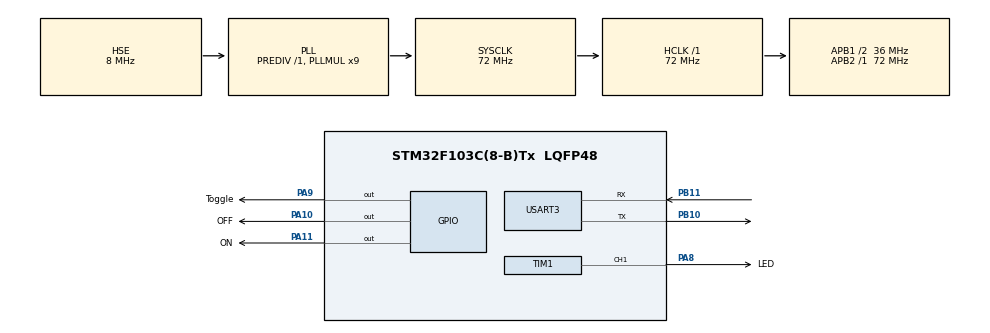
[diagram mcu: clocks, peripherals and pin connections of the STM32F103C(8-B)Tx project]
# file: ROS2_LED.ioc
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Dma.Request0=USART3_TX
Dma.Request1=USART3_RX
Dma.USART3_RX.1.Direction=DMA_PERIPH_TO_MEMORY
Dma.USART3_RX.1.Instance=DMA1_Channel3
Dma.USART3_RX.1.MemDataAlignment=DMA_MDATAALIGN_BYTE
Dma.USART3_RX.1.MemInc=DMA_MINC_ENABLE
Dma.USART3_RX.1.Mode=DMA_CIRCULAR
Dma.USART3_RX.1.PeriphDataAlignment=DMA_PDATAALIGN_BYTE
Dma.USART3_RX.1.PeriphInc=DMA_PINC_DISABLE
Dma.USART3_RX.1.Priority=DMA_PRIORITY_LOW
Dma.USART3_TX.0.Direction=DMA_MEMORY_TO_PERIPH
Dma.USART3_TX.0.Instance=DMA1_Channel2
Dma.USART3_TX.0.MemDataAlignment=DMA_MDATAALIGN_BYTE
Dma.USART3_TX.0.MemInc=DMA_MINC_ENABLE
Dma.USART3_TX.0.Mode=DMA_NORMAL
Dma.USART3_TX.0.PeriphDataAlignment=DMA_PDATAALIGN_BYTE
Dma.USART3_TX.0.PeriphInc=DMA_PINC_DISABLE
Dma.USART3_TX.0.Priority=DMA_PRIORITY_LOW
Mcu.Family=STM32F1
Mcu.Name=STM32F103C(8-B)Tx
Mcu.Package=LQFP48
NVIC.DMA1_Channel2_IRQn=true\:0\:0\:false\:false\:true\:false\:true\:true
NVIC.DMA1_Channel3_IRQn=true\:0\:0\:false\:false\:true\:false\:true\:true
NVIC.PriorityGroup=NVIC_PRIORITYGROUP_4
NVIC.TIM2_IRQn=true\:0\:0\:false\:false\:true\:true\:true\:true
NVIC.USART3_IRQn=true\:0\:0\:false\:false\:true\:true\:true\:true
PA10.GPIO_Label=OFF
PA10.Signal=GPIO_Output
PA11.GPIO_Label=ON
PA11.Signal=GPIO_Output
PA13.Mode=Serial_Wire
PA13.Signal=SYS_JTMS-SWDIO
PA14.Mode=Serial_Wire
PA14.Signal=SYS_JTCK-SWCLK
PA8.GPIO_Label=LED
PA8.Signal=S_TIM1_CH1
PA9.GPIO_Label=Toggle
PA9.Signal=GPIO_Output
PB10.Mode=Asynchronous
PB10.Signal=USART3_TX
PB11.Mode=Asynchronous
PB11.Signal=USART3_RX
PD0-OSC_IN.Mode=HSE-External-Oscillator
PD0-OSC_IN.Signal=RCC_OSC_IN
PD1-OSC_OUT.Mode=HSE-External-Oscillator
PD1-OSC_OUT.Signal=RCC_OSC_OUT
ProjectManager.HeapSize=0x200
ProjectManager.StackSize=0x400
ProjectManager.TargetToolchain=MDK-ARM V5.32
RCC.AHBFreq_Value=72000000
RCC.APB1CLKDivider=RCC_HCLK_DIV2
RCC.APB1Freq_Value=36000000
RCC.APB1TimFreq_Value=72000000
RCC.APB2Freq_Value=72000000
RCC.APB2TimFreq_Value=72000000
RCC.HCLKFreq_Value=72000000
RCC.PLLMUL=RCC_PLL_MUL9
RCC.PLLSourceVirtual=RCC_PLLSOURCE_HSE
RCC.SYSCLKFreq_VALUE=72000000
RCC.SYSCLKSource=RCC_SYSCLKSOURCE_PLLCLK
RCC.USBFreq_Value=72000000
SH.S_TIM1_CH1.0=TIM1_CH1,PWM Generation1 CH1
TIM1.Channel-PWM\ Generation1\ CH1=TIM_CHANNEL_1
TIM1.Period=500-1
TIM1.Prescaler=72-1
TIM2.Period=2000-1
TIM2.Prescaler=7200-1
USART3.VirtualMode=VM_ASYNC
VP_TIM2_VS_ClockSourceINT.Mode=Internal
board=custom

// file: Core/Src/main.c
/* USER CODE BEGIN Header */
/**
  ******************************************************************************
  * @file           : main.c
  * @brief          : Main program body
  ******************************************************************************
  * @attention
  *
  * Copyright (c) 2026 STMicroelectronics.
  * All rights reserved.
  *
  * This software is licensed under terms that can be found in the LICENSE file
  * in the root directory of this software component.
  * If no LICENSE file comes with this software, it is provided AS-IS.
  *
  ******************************************************************************
  */
/* USER CODE END Header */
#include "main.h"
#include "dma.h"
#include "tim.h"
#include "usart.h"
#include "gpio.h"

/* USER CODE BEGIN Includes */
#include "SM.h"
/* USER CODE END Includes */

void SystemClock_Config(void);

int main(void)
{

  /* MCU Configuration--------------------------------------------------------*/

  /* Reset of all peripherals, Initializes the Flash interface and the Systick. */
  HAL_Init();

  /* Configure the system clock */
  SystemClock_Config();

  /* Initialize all configured peripherals */
  MX_GPIO_Init();
  MX_DMA_Init();
  MX_TIM1_Init();
  MX_USART3_UART_Init();
  MX_TIM2_Init();
  /* USER CODE BEGIN 2 */
  HAL_TIM_Base_Start(&htim1);
	HAL_TIM_Base_Start_IT(&htim2);
  HAL_UARTEx_ReceiveToIdle_DMA(&huart3, (uint8_t*)rx_buffer, sizeof(rx_buffer));
  /* USER CODE END 2 */

  /* Infinite loop */
  while (1)
  {

  }
}

void SystemClock_Config(void)
{
  RCC_OscInitTypeDef RCC_OscInitStruct = {0};
  RCC_ClkInitTypeDef RCC_ClkInitStruct = {0};

  /** Initializes the RCC Oscillators according to the specified parameters
  * in the RCC_OscInitTypeDef structure.
  */
  RCC_OscInitStruct.OscillatorType = RCC_OSCILLATORTYPE_HSE;
  RCC_OscInitStruct.HSEState = RCC_HSE_ON;
  RCC_OscInitStruct.HSEPredivValue = RCC_HSE_PREDIV_DIV1;
  RCC_OscInitStruct.HSIState = RCC_HSI_ON;
  RCC_OscInitStruct.PLL.PLLState = RCC_PLL_ON;
  RCC_OscInitStruct.PLL.PLLSource = RCC_PLLSOURCE_HSE;
  RCC_OscInitStruct.PLL.PLLMUL = RCC_PLL_MUL9;
  if (HAL_RCC_OscConfig(&RCC_OscInitStruct) != HAL_OK)
  {
    Error_Handler();
  }

  /** Initializes the CPU, AHB and APB buses clocks
  */
  RCC_ClkInitStruct.ClockType = RCC_CLOCKTYPE_HCLK|RCC_CLOCKTYPE_SYSCLK
                              |RCC_CLOCKTYPE_PCLK1|RCC_CLOCKTYPE_PCLK2;
  RCC_ClkInitStruct.SYSCLKSource = RCC_SYSCLKSOURCE_PLLCLK;
  RCC_ClkInitStruct.AHBCLKDivider = RCC_SYSCLK_DIV1;
  RCC_ClkInitStruct.APB1CLKDivider = RCC_HCLK_DIV2;
  RCC_ClkInitStruct.APB2CLKDivider = RCC_HCLK_DIV1;

  if (HAL_RCC_ClockConfig(&RCC_ClkInitStruct, FLASH_LATENCY_2) != HAL_OK)
  {
    Error_Handler();
  }
}

/* USER CODE BEGIN 4 */
//下位机发给上位机
void HAL_TIM_PeriodElapsedCallback(TIM_HandleTypeDef *htim)
{
	if(htim->Instance == TIM2)
	{
		stm32_to_ros2();
	}
}
//下位机接收上位机
void HAL_UARTEx_RxEventCallback(UART_HandleTypeDef *huart, uint16_t Size)
{
  if (huart->Instance == USART3)
  {
    SM_UART(&rx_buf);
  }
}
/* USER CODE END 4 */

void Error_Handler(void)
{
  __disable_irq();
  while (1)
  {
  }
}
